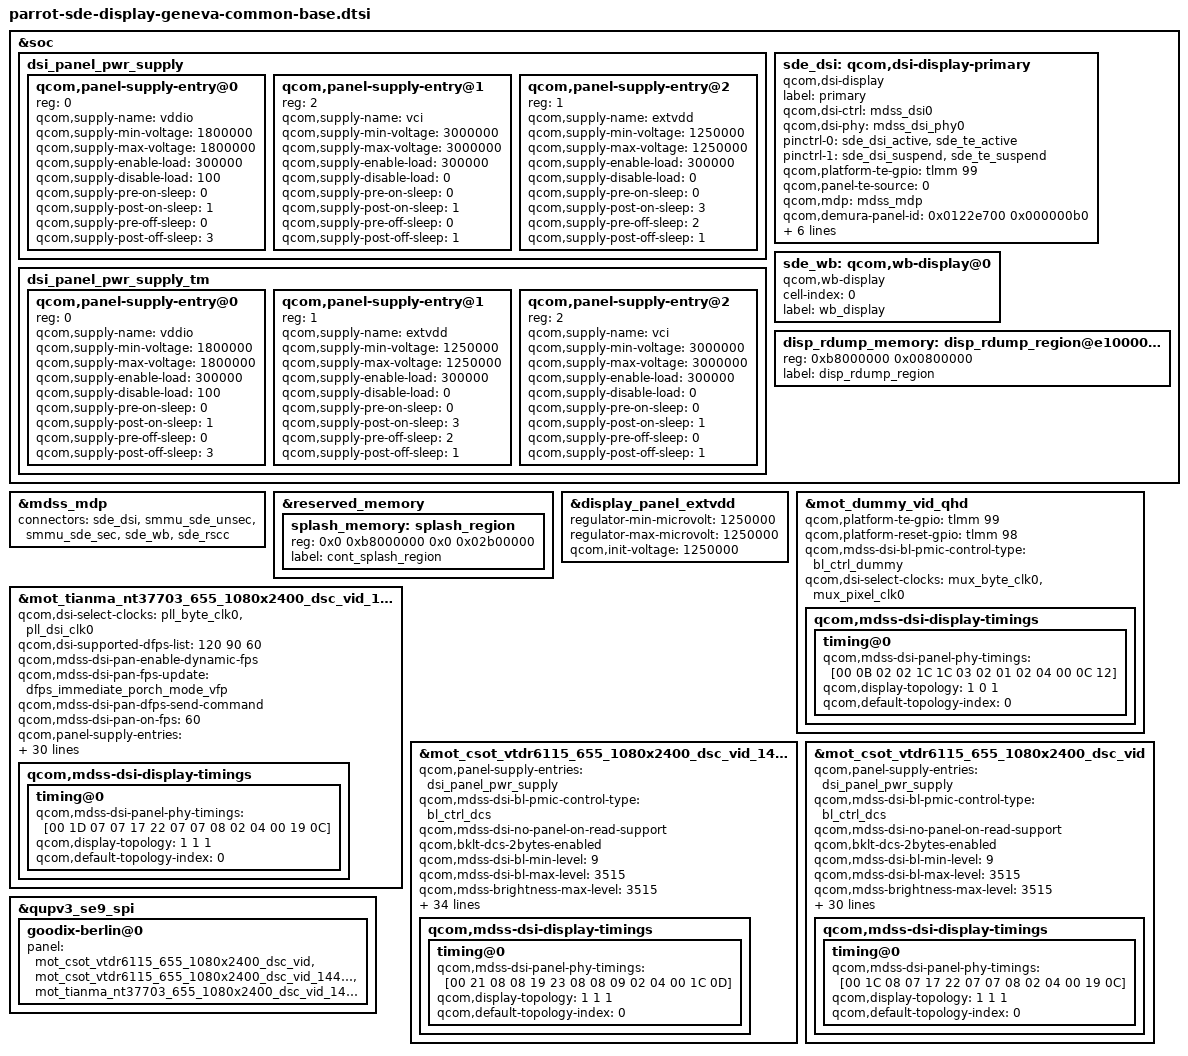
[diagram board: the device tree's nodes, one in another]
/*
   this is original from cape-sde-display-hiphi-common-base.dtsi
*/
#include <dt-bindings/clock/qcom,gcc-parrot.h>
#include <dt-bindings/clock/qcom,rpmh.h>
#include "parrot-sde-display-pinctrl.dtsi"
#include "dsi-panel-mot-dummy-qhd-video.dtsi"
#include <dt-bindings/clock/qcom,dispcc-parrot.h>
#include "dsi-panel-vtdr6115-geneva-1080x2400-video-common.dtsi"
#include "dsi-panel-vtdr6115-geneva-1080x2400-video-144hz-common.dtsi"
#include "dsi-panel-mot-tianma-nt37703-geneva-655-1080x2400-dsc-video-144hz-common.dtsi"

&soc {
	dsi_panel_pwr_supply: dsi_panel_pwr_supply {
		#address-cells = <1>;
		#size-cells = <0>;

		qcom,panel-supply-entry@0 {
			reg = <0>;
			qcom,supply-name = "vddio";
			qcom,supply-min-voltage = <1800000>;
			qcom,supply-max-voltage = <1800000>;
			qcom,supply-enable-load = <300000>;
			qcom,supply-disable-load = <100>;
			qcom,supply-pre-on-sleep = <0>;
			qcom,supply-post-on-sleep = <1>;
			qcom,supply-pre-off-sleep = <0>;
			qcom,supply-post-off-sleep = <3>;
		};

		qcom,panel-supply-entry@1 {
			reg = <2>;
			qcom,supply-name = "vci";
			qcom,supply-min-voltage = <3000000>;
			qcom,supply-max-voltage = <3000000>;
			qcom,supply-enable-load = <300000>;
			qcom,supply-disable-load = <0>;
			qcom,supply-pre-on-sleep = <0>;
			qcom,supply-post-on-sleep = <1>;
			qcom,supply-pre-off-sleep = <0>;
			qcom,supply-post-off-sleep = <1>;
		};

		qcom,panel-supply-entry@2 {
			reg = <1>;
			qcom,supply-name = "extvdd";
			qcom,supply-min-voltage = <1250000>;
			qcom,supply-max-voltage = <1250000>;
			qcom,supply-enable-load = <300000>;
			qcom,supply-disable-load = <0>;
			qcom,supply-pre-on-sleep = <0>;
			qcom,supply-post-on-sleep = <3>;
			qcom,supply-pre-off-sleep = <2>;
			qcom,supply-post-off-sleep = <1>;
		};
	};


	dsi_panel_pwr_supply_tm: dsi_panel_pwr_supply_tm {
		#address-cells = <1>;
		#size-cells = <0>;

		qcom,panel-supply-entry@0 {
			reg = <0>;
			qcom,supply-name = "vddio";
			qcom,supply-min-voltage = <1800000>;
			qcom,supply-max-voltage = <1800000>;
			qcom,supply-enable-load = <300000>;
			qcom,supply-disable-load = <100>;
			qcom,supply-pre-on-sleep = <0>;
			qcom,supply-post-on-sleep = <1>;
			qcom,supply-pre-off-sleep = <0>;
			qcom,supply-post-off-sleep = <3>;
		};


		qcom,panel-supply-entry@1 {
			reg = <1>;
			qcom,supply-name = "extvdd";
			qcom,supply-min-voltage = <1250000>;
			qcom,supply-max-voltage = <1250000>;
			qcom,supply-enable-load = <300000>;
			qcom,supply-disable-load = <0>;
			qcom,supply-pre-on-sleep = <0>;
			qcom,supply-post-on-sleep = <3>;
			qcom,supply-pre-off-sleep = <2>;
			qcom,supply-post-off-sleep = <1>;
		};

		qcom,panel-supply-entry@2 {
			reg = <2>;
			qcom,supply-name = "vci";
			qcom,supply-min-voltage = <3000000>;
			qcom,supply-max-voltage = <3000000>;
			qcom,supply-enable-load = <300000>;
			qcom,supply-disable-load = <0>;
			qcom,supply-pre-on-sleep = <0>;
			qcom,supply-post-on-sleep = <1>;
			qcom,supply-pre-off-sleep = <0>;
			qcom,supply-post-off-sleep = <1>;
		};

	};

	sde_dsi: qcom,dsi-display-primary {
		compatible = "qcom,dsi-display";
		label = "primary";

		qcom,dsi-ctrl = <&mdss_dsi0>;
		qcom,dsi-phy = <&mdss_dsi_phy0>;

		pinctrl-names = "panel_active", "panel_suspend";
		pinctrl-0 = <&sde_dsi_active &sde_te_active>;
		pinctrl-1 = <&sde_dsi_suspend &sde_te_suspend>;

		qcom,platform-te-gpio = <&tlmm 99 0>;
		qcom,panel-te-source = <0>;

		qcom,mdp = <&mdss_mdp>;
		qcom,demura-panel-id = <0x0122e700 0x000000b0>;
	};
};

&soc {
	sde_wb: qcom,wb-display@0 {
		compatible = "qcom,wb-display";
		cell-index = <0>;
		label = "wb_display";
	};

	disp_rdump_memory: disp_rdump_region@e1000000 {
		reg = <0xb8000000 0x00800000>;
		label = "disp_rdump_region";
	};
};

&sde_dsi {
	clocks = <&mdss_dsi_phy0 0>,
			<&mdss_dsi_phy0 1>,
			 /*
			  * Currently the dsi clock handles are under the dsi
			  * controller DT node. As soon as the controller probe
			  * finishes, the dispcc sync state can get called before
			  * the dsi_display probe potentially disturbing the clock
			  * votes for cont_splash use case. Hence we are no longer
			  * protected by the component model in this case against the
			  * disp cc sync state getting triggered after the dsi_ctrl
			  * probe. To protect against this incorrect sync state trigger
			  * add this dummy MDP clk vote handle to the dsi_display
			  * DT node. Since the dsi_display driver does not parse
			  * MDP clock nodes, no actual vote shall be added and this
			  * change is done just to satisfy sync state requirements.
			  */
			 <&dispcc DISP_CC_MDSS_MDP_CLK>;
	clock-names = "pll_byte_clk0", "pll_dsi_clk0",
			"mdp_core_clk";
};

&mdss_mdp {
	connectors = <&sde_dsi &smmu_sde_unsec &smmu_sde_sec &sde_wb &sde_rscc>;
};

&reserved_memory {
	splash_memory: splash_region {
		reg = <0x0 0xb8000000 0x0 0x02b00000>;
		label = "cont_splash_region";
	};
};

&sde_dsi {
	vddio-supply = <&display_panel_vddio>;
	extvdd-supply = <&display_panel_extvdd>;
	vci-supply = <&L4E>;
	qcom,dsi-default-panel = <&mot_dummy_vid_qhd>;
};

&display_panel_extvdd {
	regulator-min-microvolt = <1250000>;
	regulator-max-microvolt = <1250000>;
	qcom,init-voltage = <1250000>;
};

&mot_dummy_vid_qhd {
	qcom,platform-te-gpio = <&tlmm 99 0>;
	qcom,platform-reset-gpio = <&tlmm 98 0>;

	qcom,mdss-dsi-bl-pmic-control-type = "bl_ctrl_dummy";

	qcom,dsi-select-clocks = "mux_byte_clk0", "mux_pixel_clk0";

	qcom,mdss-dsi-display-timings {
		timing@0 {
			qcom,mdss-dsi-panel-phy-timings = [00 0B 02 02 1C 1C 03
							02 01 02 04 00 0C 12];
			qcom,display-topology = <1 0 1>;
			qcom,default-topology-index = <0>;
		};
	};
};


&mot_tianma_nt37703_655_1080x2400_dsc_vid_144hz {
	qcom,dsi-select-clocks = "pll_byte_clk0", "pll_dsi_clk0";

	qcom,dsi-supported-dfps-list = <120 90 60>;
	qcom,mdss-dsi-pan-enable-dynamic-fps;
	qcom,mdss-dsi-pan-fps-update = "dfps_immediate_porch_mode_vfp";
	qcom,mdss-dsi-pan-dfps-send-command;
	qcom,mdss-dsi-pan-on-fps = <60>;

	//qcom,dsi-dyn-clk-enable;

	qcom,panel-supply-entries = <&dsi_panel_pwr_supply_tm>;
	qcom,mdss-dsi-no-panel-on-read-support;
	qcom,mdss-dsi-bl-pmic-control-type = "bl_ctrl_dcs";
	qcom,bklt-dcs-2bytes-enabled;
	qcom,mdss-dsi-bl-min-level = <1>;
	qcom,mdss-dsi-bl-max-level = <4095>;
	//qcom,mdss-dsi-bl-default-level = <1024>;
	qcom,mdss-brightness-max-level = <4095>;
	qcom,platform-reset-gpio = <&tlmm 98 0>;
	qcom,platform-te-gpio = <&tlmm 99 0>;
	qcom,bl-dsc-cmd-state = "dsi_hs_mode";
	qcom,mdss-dsi-bl-is-exponent;

	qcom,mdss-dsi-panel-hdr-enabled;
	qcom,mdss-dsi-panel-hdr-color-primaries = <14950 15750 34000
	        16000 13000 35500 7000 2500>;
	qcom,mdss-dsi-panel-peak-brightness = <5000000>;
	qcom,mdss-dsi-panel-blackness-level = <100>;

	qcom,mdss-dsi-panel-status-check-mode = "reg_read";
	qcom,mdss-dsi-panel-status-command = [06 01 00 01 00 00 01 0A];
	qcom,mdss-dsi-panel-status-command-state = "dsi_lp_mode";
	qcom,mdss-dsi-panel-status-value = <0x9C>;
	qcom,mdss-dsi-panel-status-read-length = <1>;
	qcom,esd-check-enabled;

	qcom,cellid-read-enabled;
	qcom,mdss-dsi-panel-cellid-read-length = <23>;
	qcom,mdss-dsi-panel-cellid-command = [
		39 01 00 00 00 00 03 F0 AA 10
		06 01 00 01 00 00 01 AC];

	qcom,mdss-dsi-display-timings {
		timing@0 {
			//qcom,mdss-dsi-panel-clockrate = <400000000>;
			qcom,mdss-dsi-panel-phy-timings = [00 1D 07 07 17 22 07
				07 08 02 04 00 19 0C];
			qcom,display-topology = <1 1 1>;
			qcom,default-topology-index = <0>;
		};
	};
};

&mot_csot_vtdr6115_655_1080x2400_dsc_vid_144hz {
	qcom,panel-supply-entries = <&dsi_panel_pwr_supply>;
	qcom,mdss-dsi-bl-pmic-control-type = "bl_ctrl_dcs";
	//qcom,mdss-dsi-sec-bl-pmic-control-type = "bl_ctrl_dcs";
	qcom,mdss-dsi-no-panel-on-read-support;
	qcom,bklt-dcs-2bytes-enabled;
	qcom,mdss-dsi-bl-min-level = <9>;
	qcom,mdss-dsi-bl-max-level = <3515>;
	qcom,mdss-brightness-max-level = <3515>;
	qcom,mdss-dsi-bl-default-level = <3481>;
	qcom,platform-reset-gpio = <&tlmm 98 0>;
	qcom,platform-te-gpio = <&tlmm 99 0>;
	//qcom,platform-vio-enable-gpio = <&pm6150l_gpios 9 0>;
	qcom,bl-dsc-cmd-state = "dsi_hs_mode";
        qcom,mdss-dsi-bl-inverted-dbv;
	qcom,mdss-dsi-bl-is-exponent;

	qcom,ulps-enabled;
	qcom,suspend-ulps-enabled;

	qcom,mdss-dsi-panel-hdr-enable;
	qcom,mdss-dsi-panel-hdr-color-primaries = <14950 15750 34000
					16000 13000 35500 7000 2500>;
	qcom,mdss-dsi-panel-peak-brightness = <5000000>;
	qcom,mdss-dsi-panel-blackness-level = <100>;

	qcom,dsi-select-clocks = "pll_byte_clk0", "pll_dsi_clk0";

	qcom,dsi-supported-dfps-list = <120 90 60>;
	qcom,mdss-dsi-pan-enable-dynamic-fps;
	qcom,mdss-dsi-pan-fps-update = "dfps_immediate_porch_mode_vfp";
	qcom,mdss-dsi-pan-dfps-send-command;
	qcom,mdss-dsi-pan-on-fps = <60>;

	qcom,esd-check-enabled;
	qcom,mdss-dsi-panel-status-check-mode = "reg_read";
	qcom,mdss-dsi-panel-status-command = [06 01 00 01 00 00 01 66];
	qcom,mdss-dsi-panel-status-command-state = "dsi_lp_mode";
	qcom,mdss-dsi-panel-status-value = <0 0 0>;
	qcom,mdss-dsi-panel-status-read-length = <3>;

	qcom,cellid-read-enabled;
	qcom,mdss-dsi-panel-cellid-read-length = <23>;
	qcom,mdss-dsi-panel-cellid-command = [06 01 00 01 00 00 01 C8];

	qcom,mdss-dsi-display-timings {
		timing@0 {
			qcom,mdss-dsi-panel-phy-timings = [00 21 08 08 19 23 08
				08 09 02 04 00 1C 0D];
			qcom,display-topology = <1 1 1>;
			qcom,default-topology-index = <0>;
		};
	};
};


&mot_csot_vtdr6115_655_1080x2400_dsc_vid{
	qcom,panel-supply-entries = <&dsi_panel_pwr_supply>;
	qcom,mdss-dsi-bl-pmic-control-type = "bl_ctrl_dcs";
	//qcom,mdss-dsi-sec-bl-pmic-control-type = "bl_ctrl_dcs";
	qcom,mdss-dsi-no-panel-on-read-support;
	qcom,bklt-dcs-2bytes-enabled;
	qcom,mdss-dsi-bl-min-level = <9>;
	qcom,mdss-dsi-bl-max-level = <3515>;
	qcom,mdss-brightness-max-level = <3515>;
	qcom,mdss-dsi-bl-default-level = <3481>;
	qcom,platform-reset-gpio = <&tlmm 98 0>;
	qcom,platform-te-gpio = <&tlmm 99 0>;
	//qcom,platform-vio-enable-gpio = <&pm6150l_gpios 9 0>;
	qcom,bl-dsc-cmd-state = "dsi_hs_mode";
        qcom,mdss-dsi-bl-inverted-dbv;
	qcom,mdss-dsi-bl-is-exponent;

	qcom,ulps-enabled;
	qcom,suspend-ulps-enabled;

	qcom,mdss-dsi-panel-hdr-enable;
	qcom,mdss-dsi-panel-hdr-color-primaries = <14950 15750 34000
					16000 13000 35500 7000 2500>;
	qcom,mdss-dsi-panel-peak-brightness = <5000000>;
	qcom,mdss-dsi-panel-blackness-level = <100>;

	qcom,dsi-select-clocks = "pll_byte_clk0", "pll_dsi_clk0";

	qcom,dsi-supported-dfps-list = <120 90 60 48>;
	qcom,mdss-dsi-pan-enable-dynamic-fps;
	qcom,mdss-dsi-pan-fps-update = "dfps_immediate_porch_mode_vfp";
	qcom,mdss-dsi-pan-dfps-send-command;
	qcom,mdss-dsi-pan-on-fps = <60>;

	qcom,esd-check-enabled;
	qcom,mdss-dsi-panel-status-check-mode = "reg_read";
	qcom,mdss-dsi-panel-status-command = [06 01 00 01 00 00 01 66];
	qcom,mdss-dsi-panel-status-command-state = "dsi_lp_mode";
	qcom,mdss-dsi-panel-status-value = <0 0 0>;
	qcom,mdss-dsi-panel-status-read-length = <3>;

	qcom,mdss-dsi-display-timings {
		timing@0 {
			qcom,mdss-dsi-panel-phy-timings = [00 1C 08 07 17 22 07
				07 08 02 04 00 19 0C];
			qcom,display-topology = <1 1 1>;
			qcom,default-topology-index = <0>;
		};
	};

};

&qupv3_se9_spi {
	goodix-berlin@0 {
		panel = <&mot_csot_vtdr6115_655_1080x2400_dsc_vid
				&mot_csot_vtdr6115_655_1080x2400_dsc_vid_144hz
				&mot_tianma_nt37703_655_1080x2400_dsc_vid_144hz>;
	};
};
